AUTOSAR XML (schema 00049)
package /RB/PT/PCT_DcmSample_Provider/SwComponentTypes
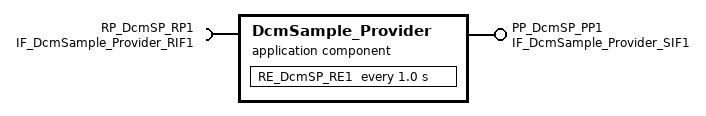
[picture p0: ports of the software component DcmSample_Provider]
  application sw component type DcmSample_Provider
    provide port PP_DcmSP_PP1: provided-interface=IF_DcmSample_Provider_SIF1
    require port RP_DcmSP_RP1: required-interface=IF_DcmSample_Provider_RIF1
    behavior IB_DcmSP_IB1: data-type-mapping=DTMS_DcmSP_uint8
      timing event TE_DcmSP_TE1: start-on-event=RE_DcmSP_RE1, period=1.0
      runnable RE_DcmSP_RE1: symbol=DcmSample_Provider_1000ms
        data-receive-point-by-values:
          access DRP_DcmSP_DRP1: accessed-variable=RP_DcmSP_RP1.VDP_DcmSP_RVDP1
        data-send-points:
          access DSP_DcmSP_DSP1: accessed-variable=PP_DcmSP_PP1.VDP_DcmSP_SVDP1
package /RB/PT/PCT_DcmSample_Provider/PortInterfaces
  sender receiver interface IF_DcmSample_Provider_SIF1
    data VDP_DcmSP_SVDP1: type=ADT_DcmSP_uint8
  sender receiver interface IF_DcmSample_Provider_RIF1
    data VDP_DcmSP_RVDP1: type=ADT_DcmSP_uint8
package /RB/PT/PCT_DcmSample_Provider/ApplicationDataTypes
  app type ADT_DcmSP_uint8: category=VALUE, sw-calibration-access=READ-ONLY
package /RB/PT/PCT_DcmSample_Provider/ImplementationDataTypes
  impl type IDT_DcmSP_uint8: implementation-data-type=uint8
package /RB/PT/PCT_DcmSample_Provider/DataTypeMappingSets
  data type mapping set DTMS_DcmSP_uint8: data-type-map{application-data-type=ADT_DcmSP_uint8, implementation-data-type=IDT_DcmSP_uint8}
package /RB/PT/PCT_DcmSample_Provider/PortInterfaceMappingSets
  port interface mapping set PIMSet_IF_DcmSample_Provider_RIF1_IF_DcmSample_Requester_SIF1
    port-interface-mappings:
      variable and parameter interface mapping PIM_VDP_DcmSP_RVDP1_VDP_DcmSR_SVDP1: data-prototype-mapping{first-data-prototype=VDP_DcmSP_RVDP1, second-data-prototype=VDP_DcmSR_SVDP1}
